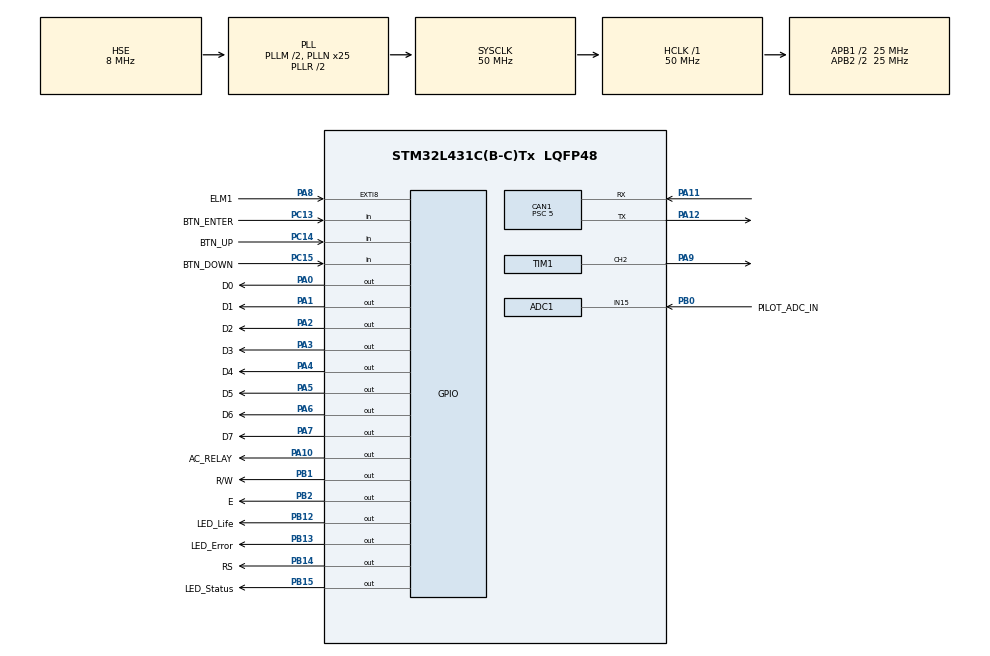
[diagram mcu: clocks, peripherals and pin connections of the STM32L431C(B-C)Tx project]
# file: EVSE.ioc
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ADC1.Channel-0\#ChannelRegularConversion=ADC_CHANNEL_15
ADC1.EnableAnalogWatchDog1=false
ADC1.ExternalTrigConv=ADC_EXTERNALTRIG_T1_TRGO
ADC1.ExternalTrigConvEdge=ADC_EXTERNALTRIGCONVEDGE_FALLING
ADC1.NbrOfConversionFlag=1
ADC1.OffsetNumber-0\#ChannelRegularConversion=ADC_OFFSET_NONE
ADC1.Rank-0\#ChannelRegularConversion=1
ADC1.SamplingTime-0\#ChannelRegularConversion=ADC_SAMPLETIME_2CYCLES_5
ADC1.master=1
CAN1.ABOM=ENABLE
CAN1.BS1=CAN_BS1_15TQ
CAN1.BS2=CAN_BS2_4TQ
CAN1.CalculateBaudRate=250000
CAN1.CalculateTimeBit=4000
CAN1.CalculateTimeQuantum=200.0
CAN1.NART=ENABLE
CAN1.Prescaler=5
CAN1.TXFP=ENABLE
Dma.ADC1.0.Direction=DMA_PERIPH_TO_MEMORY
Dma.ADC1.0.Instance=DMA1_Channel1
Dma.ADC1.0.MemDataAlignment=DMA_MDATAALIGN_HALFWORD
Dma.ADC1.0.MemInc=DMA_MINC_ENABLE
Dma.ADC1.0.Mode=DMA_NORMAL
Dma.ADC1.0.PeriphDataAlignment=DMA_PDATAALIGN_HALFWORD
Dma.ADC1.0.PeriphInc=DMA_PINC_DISABLE
Dma.ADC1.0.Priority=DMA_PRIORITY_LOW
Dma.Request0=ADC1
IWDG.Prescaler=IWDG_PRESCALER_256
IWDG.Reload=375
Mcu.Family=STM32L4
Mcu.Name=STM32L431C(B-C)Tx
Mcu.Package=LQFP48
NVIC.ADC1_IRQn=true\:0\:0\:false\:false\:true\:true\:true\:true
NVIC.CAN1_RX0_IRQn=true\:0\:0\:false\:false\:true\:true\:true\:true
NVIC.CAN1_RX1_IRQn=true\:0\:0\:false\:false\:true\:true\:true\:true
NVIC.CAN1_TX_IRQn=true\:0\:0\:false\:false\:true\:true\:true\:true
NVIC.DMA1_Channel1_IRQn=true\:0\:0\:false\:false\:true\:false\:true\:true
NVIC.EXTI9_5_IRQn=true\:4\:0\:true\:false\:true\:true\:true\:true
NVIC.PriorityGroup=NVIC_PRIORITYGROUP_4
PA0.GPIO_Label=D0
PA0.Signal=GPIO_Output
PA1.GPIO_Label=D1
PA1.Signal=GPIO_Output
PA10.GPIO_Label=AC_RELAY
PA10.Signal=GPIO_Output
PA11.Mode=CAN_Activate
PA11.Signal=CAN1_RX
PA12.Mode=CAN_Activate
PA12.Signal=CAN1_TX
PA13\ (JTMS-SWDIO).Mode=JTAG_5_pins
PA13\ (JTMS-SWDIO).Signal=SYS_JTMS-SWDIO
PA14\ (JTCK-SWCLK).Mode=JTAG_5_pins
PA14\ (JTCK-SWCLK).Signal=SYS_JTCK-SWCLK
PA15\ (JTDI).Mode=JTAG_5_pins
PA15\ (JTDI).Signal=SYS_JTDI
PA2.GPIO_Label=D2
PA2.Signal=GPIO_Output
PA3.GPIO_Label=D3
PA3.Signal=GPIO_Output
PA4.GPIO_Label=D4
PA4.Signal=GPIO_Output
PA5.GPIO_Label=D5
PA5.Signal=GPIO_Output
PA6.GPIO_Label=D6
PA6.Signal=GPIO_Output
PA7.GPIO_Label=D7
PA7.Signal=GPIO_Output
PA8.GPIO_Label=ELM1
PA8.Signal=GPXTI8
PA9.Signal=S_TIM1_CH2
PB0.GPIO_Label=PILOT_ADC_IN
PB0.Signal=ADCx_IN15
PB1.GPIO_Label=R/W
PB1.Signal=GPIO_Output
PB12.GPIO_Label=LED_Life
PB12.Signal=GPIO_Output
PB13.GPIO_Label=LED_Error
PB13.Signal=GPIO_Output
PB14.GPIO_Label=RS
PB14.Signal=GPIO_Output
PB15.GPIO_Label=LED_Status
PB15.Signal=GPIO_Output
PB2.GPIO_Label=E
PB2.Signal=GPIO_Output
PB3\ (JTDO-TRACESWO).Mode=JTAG_5_pins
PB3\ (JTDO-TRACESWO).Signal=SYS_JTDO-SWO
PB4\ (NJTRST).Mode=JTAG_5_pins
PB4\ (NJTRST).Signal=SYS_JTRST
PC13.GPIO_Label=BTN_ENTER
PC13.GPIO_PuPd=GPIO_PULLUP
PC13.Signal=GPIO_Input
PC14-OSC32_IN\ (PC14).GPIO_Label=BTN_UP
PC14-OSC32_IN\ (PC14).GPIO_PuPd=GPIO_PULLUP
PC14-OSC32_IN\ (PC14).Signal=GPIO_Input
PC15-OSC32_OUT\ (PC15).GPIO_Label=BTN_DOWN
PC15-OSC32_OUT\ (PC15).GPIO_PuPd=GPIO_PULLUP
PC15-OSC32_OUT\ (PC15).Signal=GPIO_Input
PH0-OSC_IN\ (PH0).Mode=HSE-External-Oscillator
PH0-OSC_IN\ (PH0).Signal=RCC_OSC_IN
PH1-OSC_OUT\ (PH1).Mode=HSE-External-Oscillator
PH1-OSC_OUT\ (PH1).Signal=RCC_OSC_OUT
ProjectManager.HeapSize=0x200
ProjectManager.StackSize=0x400
ProjectManager.TargetToolchain=STM32CubeIDE
RCC.ADCFreq_Value=52000000
RCC.AHBFreq_Value=50000000
RCC.APB1CLKDivider=RCC_HCLK_DIV2
RCC.APB1Freq_Value=25000000
RCC.APB1TimFreq_Value=50000000
RCC.APB2CLKDivider=RCC_HCLK_DIV2
RCC.APB2Freq_Value=25000000
RCC.APB2TimFreq_Value=50000000
RCC.CortexFreq_Value=50000000
RCC.HCLKFreq_Value=50000000
RCC.HSE_VALUE=8000000
RCC.HSI48_VALUE=48000000
RCC.HSI_VALUE=16000000
RCC.LSE_VALUE=32768
RCC.MSI_VALUE=4000000
RCC.PLLM=2
RCC.PLLN=25
RCC.PLLSAI1N=26
RCC.PLLSourceVirtual=RCC_PLLSOURCE_HSE
RCC.RTCClockSelection=RCC_RTCCLKSOURCE_HSE_DIV32
RCC.SYSCLKFreq_VALUE=50000000
RCC.SYSCLKSource=RCC_SYSCLKSOURCE_PLLCLK
RCC.VCOOutputFreq_Value=100000000
RTC.AsynchPrediv=124
RTC.SynchPrediv=1999
SH.ADCx_IN15.0=ADC1_IN15,IN15-Single-Ended
SH.S_TIM1_CH2.0=TIM1_CH2,PWM Generation2 CH2
TIM1.Channel-PWM\ Generation1\ No\ Output=TIM_CHANNEL_1
TIM1.Channel-PWM\ Generation2\ CH2=TIM_CHANNEL_2
TIM1.OCIdleState_1=TIM_OCIDLESTATE_SET
TIM1.OCIdleState_2=TIM_OCIDLESTATE_RESET
TIM1.Period=1000
TIM1.Prescaler=49
TIM1.Pulse-PWM\ Generation1\ No\ Output=50
TIM1.TIM_MasterOutputTrigger=TIM_TRGO_OC1REF
TIM1.TIM_MasterOutputTrigger2=TIM_TRGO2_OC1REF
VP_IWDG_VS_IWDG.Mode=IWDG_Activate
VP_RTC_VS_RTC_Activate.Mode=RTC_Enabled
VP_TIM1_VS_no_output1.Mode=PWM Generation1 No Output
board=custom

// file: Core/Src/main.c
/* USER CODE BEGIN Header */
/**
  ******************************************************************************
  * @file           : main.c
  * @brief          : Main program body
  ******************************************************************************
  * @attention
  *
  * Copyright (c) 2022 STMicroelectronics.
  * All rights reserved.
  *
  * This software is licensed under terms that can be found in the LICENSE file
  * in the root directory of this software component.
  * If no LICENSE file comes with this software, it is provided AS-IS.
  *
  ******************************************************************************
  */
/* USER CODE END Header */
#include "main.h"

/* USER CODE BEGIN Includes */
#include "APP.h"
/* USER CODE END Includes */

 ADC_HandleTypeDef hadc1;
DMA_HandleTypeDef hdma_adc1;

CAN_HandleTypeDef hcan1;

IWDG_HandleTypeDef hiwdg;

RTC_HandleTypeDef hrtc;

TIM_HandleTypeDef htim1;

void SystemClock_Config(void);
static void MX_GPIO_Init(void);
static void MX_CAN1_Init(void);
static void MX_DMA_Init(void);
static void MX_TIM1_Init(void);
static void MX_ADC1_Init(void);
static void MX_IWDG_Init(void);
static void MX_RTC_Init(void);

int main(void)
{

  /* MCU Configuration--------------------------------------------------------*/

  /* Reset of all peripherals, Initializes the Flash interface and the Systick. */
  HAL_Init();

  /* Configure the system clock */
  SystemClock_Config();

  /* Initialize all configured peripherals */
  MX_GPIO_Init();
  MX_CAN1_Init();
  MX_DMA_Init();
  MX_TIM1_Init();
  MX_ADC1_Init();
  MX_IWDG_Init();
  MX_RTC_Init();

  /* Infinite loop */
  /* USER CODE BEGIN WHILE */

  APP_Init();
  APP_Start();

  while (1)
  {
    /* USER CODE END WHILE */

  }
}

void SystemClock_Config(void)
{
  RCC_OscInitTypeDef RCC_OscInitStruct = {0};
  RCC_ClkInitTypeDef RCC_ClkInitStruct = {0};

  /** Configure the main internal regulator output voltage
  */
  if (HAL_PWREx_ControlVoltageScaling(PWR_REGULATOR_VOLTAGE_SCALE1) != HAL_OK)
  {
    Error_Handler();
  }

  /** Initializes the RCC Oscillators according to the specified parameters
  * in the RCC_OscInitTypeDef structure.
  */
  RCC_OscInitStruct.OscillatorType = RCC_OSCILLATORTYPE_LSI|RCC_OSCILLATORTYPE_HSE;
  RCC_OscInitStruct.HSEState = RCC_HSE_ON;
  RCC_OscInitStruct.LSIState = RCC_LSI_ON;
  RCC_OscInitStruct.PLL.PLLState = RCC_PLL_ON;
  RCC_OscInitStruct.PLL.PLLSource = RCC_PLLSOURCE_HSE;
  RCC_OscInitStruct.PLL.PLLM = 2;
  RCC_OscInitStruct.PLL.PLLN = 25;
  RCC_OscInitStruct.PLL.PLLP = RCC_PLLP_DIV7;
  RCC_OscInitStruct.PLL.PLLQ = RCC_PLLQ_DIV2;
  RCC_OscInitStruct.PLL.PLLR = RCC_PLLR_DIV2;
  if (HAL_RCC_OscConfig(&RCC_OscInitStruct) != HAL_OK)
  {
    Error_Handler();
  }

  /** Initializes the CPU, AHB and APB buses clocks
  */
  RCC_ClkInitStruct.ClockType = RCC_CLOCKTYPE_HCLK|RCC_CLOCKTYPE_SYSCLK
                              |RCC_CLOCKTYPE_PCLK1|RCC_CLOCKTYPE_PCLK2;
  RCC_ClkInitStruct.SYSCLKSource = RCC_SYSCLKSOURCE_PLLCLK;
  RCC_ClkInitStruct.AHBCLKDivider = RCC_SYSCLK_DIV1;
  RCC_ClkInitStruct.APB1CLKDivider = RCC_HCLK_DIV2;
  RCC_ClkInitStruct.APB2CLKDivider = RCC_HCLK_DIV2;

  if (HAL_RCC_ClockConfig(&RCC_ClkInitStruct, FLASH_LATENCY_3) != HAL_OK)
  {
    Error_Handler();
  }
}

static void MX_ADC1_Init(void)
{

  ADC_ChannelConfTypeDef sConfig = {0};

  /** Common config
  */
  hadc1.Instance = ADC1;
  hadc1.Init.ClockPrescaler = ADC_CLOCK_ASYNC_DIV1;
  hadc1.Init.Resolution = ADC_RESOLUTION_12B;
  hadc1.Init.DataAlign = ADC_DATAALIGN_RIGHT;
  hadc1.Init.ScanConvMode = ADC_SCAN_DISABLE;
  hadc1.Init.EOCSelection = ADC_EOC_SINGLE_CONV;
  hadc1.Init.LowPowerAutoWait = DISABLE;
  hadc1.Init.ContinuousConvMode = DISABLE;
  hadc1.Init.NbrOfConversion = 1;
  hadc1.Init.DiscontinuousConvMode = DISABLE;
  hadc1.Init.ExternalTrigConv = ADC_EXTERNALTRIG_T1_TRGO;
  hadc1.Init.ExternalTrigConvEdge = ADC_EXTERNALTRIGCONVEDGE_FALLING;
  hadc1.Init.DMAContinuousRequests = DISABLE;
  hadc1.Init.Overrun = ADC_OVR_DATA_PRESERVED;
  hadc1.Init.OversamplingMode = DISABLE;
  if (HAL_ADC_Init(&hadc1) != HAL_OK)
  {
    Error_Handler();
  }

  /** Configure Regular Channel
  */
  sConfig.Channel = ADC_CHANNEL_15;
  sConfig.Rank = ADC_REGULAR_RANK_1;
  sConfig.SamplingTime = ADC_SAMPLETIME_2CYCLES_5;
  sConfig.SingleDiff = ADC_SINGLE_ENDED;
  sConfig.OffsetNumber = ADC_OFFSET_NONE;
  sConfig.Offset = 0;
  if (HAL_ADC_ConfigChannel(&hadc1, &sConfig) != HAL_OK)
  {
    Error_Handler();
  }

}

static void MX_CAN1_Init(void)
{

  hcan1.Instance = CAN1;
  hcan1.Init.Prescaler = 5;
  hcan1.Init.Mode = CAN_MODE_NORMAL;
  hcan1.Init.SyncJumpWidth = CAN_SJW_1TQ;
  hcan1.Init.TimeSeg1 = CAN_BS1_15TQ;
  hcan1.Init.TimeSeg2 = CAN_BS2_4TQ;
  hcan1.Init.TimeTriggeredMode = DISABLE;
  hcan1.Init.AutoBusOff = ENABLE;
  hcan1.Init.AutoWakeUp = DISABLE;
  hcan1.Init.AutoRetransmission = ENABLE;
  hcan1.Init.ReceiveFifoLocked = DISABLE;
  hcan1.Init.TransmitFifoPriority = ENABLE;
  if (HAL_CAN_Init(&hcan1) != HAL_OK)
  {
    Error_Handler();
  }

}

static void MX_IWDG_Init(void)
{

  hiwdg.Instance = IWDG;
  hiwdg.Init.Prescaler = IWDG_PRESCALER_256;
  hiwdg.Init.Window = 4095;
  hiwdg.Init.Reload = 375;
  if (HAL_IWDG_Init(&hiwdg) != HAL_OK)
  {
    Error_Handler();
  }

}

static void MX_RTC_Init(void)
{

  /** Initialize RTC Only
  */
  hrtc.Instance = RTC;
  hrtc.Init.HourFormat = RTC_HOURFORMAT_24;
  hrtc.Init.AsynchPrediv = 124;
  hrtc.Init.SynchPrediv = 1999;
  hrtc.Init.OutPut = RTC_OUTPUT_DISABLE;
  hrtc.Init.OutPutRemap = RTC_OUTPUT_REMAP_NONE;
  hrtc.Init.OutPutPolarity = RTC_OUTPUT_POLARITY_HIGH;
  hrtc.Init.OutPutType = RTC_OUTPUT_TYPE_OPENDRAIN;
  if (HAL_RTC_Init(&hrtc) != HAL_OK)
  {
    Error_Handler();
  }

}

static void MX_TIM1_Init(void)
{

  TIM_MasterConfigTypeDef sMasterConfig = {0};
  TIM_OC_InitTypeDef sConfigOC = {0};
  TIM_BreakDeadTimeConfigTypeDef sBreakDeadTimeConfig = {0};

  htim1.Instance = TIM1;
  htim1.Init.Prescaler = 49;
  htim1.Init.CounterMode = TIM_COUNTERMODE_UP;
  htim1.Init.Period = 1000;
  htim1.Init.ClockDivision = TIM_CLOCKDIVISION_DIV1;
  htim1.Init.RepetitionCounter = 0;
  htim1.Init.AutoReloadPreload = TIM_AUTORELOAD_PRELOAD_DISABLE;
  if (HAL_TIM_PWM_Init(&htim1) != HAL_OK)
  {
    Error_Handler();
  }
  sMasterConfig.MasterOutputTrigger = TIM_TRGO_OC1REF;
  sMasterConfig.MasterOutputTrigger2 = TIM_TRGO2_OC1REF;
  sMasterConfig.MasterSlaveMode = TIM_MASTERSLAVEMODE_DISABLE;
  if (HAL_TIMEx_MasterConfigSynchronization(&htim1, &sMasterConfig) != HAL_OK)
  {
    Error_Handler();
  }
  sConfigOC.OCMode = TIM_OCMODE_PWM1;
  sConfigOC.Pulse = 50;
  sConfigOC.OCPolarity = TIM_OCPOLARITY_HIGH;
  sConfigOC.OCNPolarity = TIM_OCNPOLARITY_HIGH;
  sConfigOC.OCFastMode = TIM_OCFAST_DISABLE;
  sConfigOC.OCIdleState = TIM_OCIDLESTATE_SET;
  sConfigOC.OCNIdleState = TIM_OCNIDLESTATE_RESET;
  if (HAL_TIM_PWM_ConfigChannel(&htim1, &sConfigOC, TIM_CHANNEL_1) != HAL_OK)
  {
    Error_Handler();
  }
  sConfigOC.Pulse = 0;
  sConfigOC.OCIdleState = TIM_OCIDLESTATE_RESET;
  if (HAL_TIM_PWM_ConfigChannel(&htim1, &sConfigOC, TIM_CHANNEL_2) != HAL_OK)
  {
    Error_Handler();
  }
  sBreakDeadTimeConfig.OffStateRunMode = TIM_OSSR_DISABLE;
  sBreakDeadTimeConfig.OffStateIDLEMode = TIM_OSSI_DISABLE;
  sBreakDeadTimeConfig.LockLevel = TIM_LOCKLEVEL_OFF;
  sBreakDeadTimeConfig.DeadTime = 0;
  sBreakDeadTimeConfig.BreakState = TIM_BREAK_DISABLE;
  sBreakDeadTimeConfig.BreakPolarity = TIM_BREAKPOLARITY_HIGH;
  sBreakDeadTimeConfig.BreakFilter = 0;
  sBreakDeadTimeConfig.Break2State = TIM_BREAK2_DISABLE;
  sBreakDeadTimeConfig.Break2Polarity = TIM_BREAK2POLARITY_HIGH;
  sBreakDeadTimeConfig.Break2Filter = 0;
  sBreakDeadTimeConfig.AutomaticOutput = TIM_AUTOMATICOUTPUT_DISABLE;
  if (HAL_TIMEx_ConfigBreakDeadTime(&htim1, &sBreakDeadTimeConfig) != HAL_OK)
  {
    Error_Handler();
  }
  HAL_TIM_MspPostInit(&htim1);

}

static void MX_DMA_Init(void)
{

  /* DMA controller clock enable */
  __HAL_RCC_DMA1_CLK_ENABLE();

  /* DMA interrupt init */
  /* DMA1_Channel1_IRQn interrupt configuration */
  HAL_NVIC_SetPriority(DMA1_Channel1_IRQn, 0, 0);
  HAL_NVIC_EnableIRQ(DMA1_Channel1_IRQn);

}

static void MX_GPIO_Init(void)
{
  GPIO_InitTypeDef GPIO_InitStruct = {0};

  /* GPIO Ports Clock Enable */
  __HAL_RCC_GPIOC_CLK_ENABLE();
  __HAL_RCC_GPIOH_CLK_ENABLE();
  __HAL_RCC_GPIOA_CLK_ENABLE();
  __HAL_RCC_GPIOB_CLK_ENABLE();

  /*Configure GPIO pin Output Level */
  HAL_GPIO_WritePin(GPIOA, D0_Pin|D1_Pin|D2_Pin|D3_Pin
                          |D4_Pin|D5_Pin|D6_Pin|D7_Pin
                          |AC_RELAY_Pin, GPIO_PIN_RESET);

  /*Configure GPIO pin Output Level */
  HAL_GPIO_WritePin(GPIOB, R_W_Pin|E_Pin|LED_Life_Pin|LED_Error_Pin
                          |RS_Pin|LED_Status_Pin, GPIO_PIN_RESET);

  /*Configure GPIO pins : BTN_ENTER_Pin BTN_UP_Pin BTN_DOWN_Pin */
  GPIO_InitStruct.Pin = BTN_ENTER_Pin|BTN_UP_Pin|BTN_DOWN_Pin;
  GPIO_InitStruct.Mode = GPIO_MODE_INPUT;
  GPIO_InitStruct.Pull = GPIO_PULLUP;
  HAL_GPIO_Init(GPIOC, &GPIO_InitStruct);

  /*Configure GPIO pins : D0_Pin D1_Pin D2_Pin D3_Pin
                           D4_Pin D5_Pin D6_Pin D7_Pin
                           AC_RELAY_Pin */
  GPIO_InitStruct.Pin = D0_Pin|D1_Pin|D2_Pin|D3_Pin
                          |D4_Pin|D5_Pin|D6_Pin|D7_Pin
                          |AC_RELAY_Pin;
  GPIO_InitStruct.Mode = GPIO_MODE_OUTPUT_PP;
  GPIO_InitStruct.Pull = GPIO_NOPULL;
  GPIO_InitStruct.Speed = GPIO_SPEED_FREQ_LOW;
  HAL_GPIO_Init(GPIOA, &GPIO_InitStruct);

  /*Configure GPIO pins : R_W_Pin E_Pin LED_Life_Pin LED_Error_Pin
                           RS_Pin LED_Status_Pin */
  GPIO_InitStruct.Pin = R_W_Pin|E_Pin|LED_Life_Pin|LED_Error_Pin
                          |RS_Pin|LED_Status_Pin;
  GPIO_InitStruct.Mode = GPIO_MODE_OUTPUT_PP;
  GPIO_InitStruct.Pull = GPIO_NOPULL;
  GPIO_InitStruct.Speed = GPIO_SPEED_FREQ_LOW;
  HAL_GPIO_Init(GPIOB, &GPIO_InitStruct);

  /*Configure GPIO pin : ELM1_Pin */
  GPIO_InitStruct.Pin = ELM1_Pin;
  GPIO_InitStruct.Mode = GPIO_MODE_IT_RISING;
  GPIO_InitStruct.Pull = GPIO_NOPULL;
  HAL_GPIO_Init(ELM1_GPIO_Port, &GPIO_InitStruct);

  /* EXTI interrupt init*/
  HAL_NVIC_SetPriority(EXTI9_5_IRQn, 4, 0);
  HAL_NVIC_EnableIRQ(EXTI9_5_IRQn);

}

void Error_Handler(void)
{
  __disable_irq();
  while (1)
  {
  }
}
